# AT90PWM1 register map
Vendor: Atmel; File version: 1.0
CPU: other r0p0, little endian, no MPU, no FPU, 4 interrupt priority bits
Registers are 8-bit, read-write, reset 0x0 unless marked. A register's access mark holds for its fields unless they carry their own. Offsets are from the block's base; [hi:lo] are bit positions; {n}, {i} and the like mark numbered series.

## BOOT_LOAD — Bootloader
Base 0x00800057
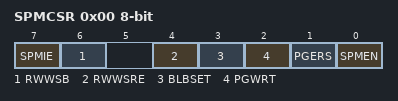
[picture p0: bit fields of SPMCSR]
0x00 SPMCSR — Store Program Memory Control Register
  [7] SPMIE — SPM Interrupt Enable
  [6] RWWSB — Read While Write Section Busy
  [4] RWWSRE — Read While Write section read enable
  [3] BLBSET — Boot Lock Bit Set
  [2] PGWRT — Page Write
  [1] PGERS — Page Erase
  [0] SPMEN — Store Program Memory Enable

## CPU — CPU Registers
Base 0x00800039
0x00 GPIOR1 — General Purpose IO Register 1
  [7:0] GPIOR — General Purpose IO Register 1 bis
0x01 GPIOR2 — General Purpose IO Register 2
  [7:0] GPIOR — General Purpose IO Register 2 bis
0x02 GPIOR3 — General Purpose IO Register 3
  [7:0] GPIOR — General Purpose IO Register 3 bis
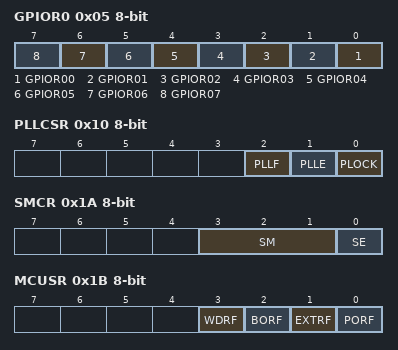
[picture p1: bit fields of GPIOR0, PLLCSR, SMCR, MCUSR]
0x05 GPIOR0 — General Purpose IO Register 0
  [n] GPIOR{n:02} (n=0..7) — General Purpose IO Register 0 bit {n}
0x10 PLLCSR — PLL Control And Status Register
  [2] PLLF — PLL Factor
  [1] PLLE — PLL Enable
  [0] PLOCK — PLL Lock Detector
0x1A SMCR — Sleep Mode Control Register
  [3:1] SM — Sleep Mode Select bits
    0=IDLE; 1=ADC (ADC Noise Reduction (If Available)); 2=PDOWN (Power Down); 6=STDBY (Standby)
  [0] SE — Sleep Enable
0x1B MCUSR — MCU Status Register
  [3] WDRF — Watchdog Reset Flag
  [2] BORF — Brown-out Reset Flag
  [1] EXTRF — External Reset Flag
  [0] PORF — Power-on reset flag
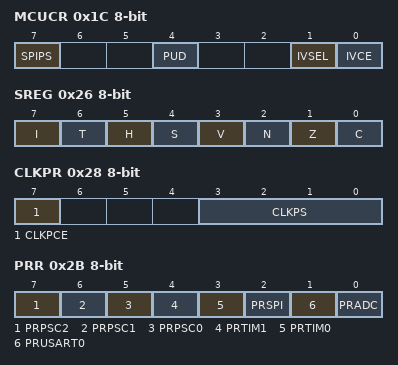
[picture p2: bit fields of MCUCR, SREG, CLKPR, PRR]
0x1C MCUCR — MCU Control Register
  [7] SPIPS — SPI Pin Select
  [4] PUD — Pull-up disable
  [1] IVSEL — Interrupt Vector Select
  [0] IVCE — Interrupt Vector Change Enable
0x24 SP 16-bit (reset mask 0xFF) — Stack Pointer
0x26 SREG — Status Register
  [7] I — Global Interrupt Enable
  [6] T — Bit Copy Storage
  [5] H — Half Carry Flag
  [4] S — Sign Bit
  [3] V — Two's Complement Overflow Flag
  [2] N — Negative Flag
  [1] Z — Zero Flag
  [0] C — Carry Flag
0x28 CLKPR
  [7] CLKPCE
  [3:0] CLKPS
    0=1; 1=2; 2=4; 3=8; 4=16; 5=32; 6=64; 7=128; 8=256
0x2B PRR — Power Reduction Register
  [7] PRPSC2 — Power Reduction PSC2
  [6] PRPSC1 — Power Reduction PSC1
  [5] PRPSC0 — Power Reduction PSC0
  [4] PRTIM1 — Power Reduction Timer/Counter1
  [3] PRTIM0 — Power Reduction Timer/Counter0
  [2] PRSPI — Power Reduction Serial Peripheral Interface
  [1] PRUSART0 — Power Reduction USART
  [0] PRADC — Power Reduction ADC
0x2D OSCCAL — Oscillator Calibration Value (read-only for debugger)
  [7:0] OSCCAL — Oscillator Calibration

## EEPROM
Base 0x0080003F
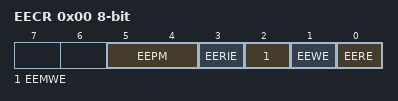
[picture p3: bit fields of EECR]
0x00 EECR — EEPROM Control Register
  [5:4] EEPM — EEPROM Programming Mode
  [3] EERIE — EEPROM Ready Interrupt Enable
  [2] EEMWE — EEPROM Master Write Enable
  [1] EEWE — EEPROM Write Enable
  [0] EERE — EEPROM Read Enable
0x01 EEDR — EEPROM Data Register
  [7:0] EEDR — EEPROM Data Bits
0x02 EEAR 16-bit (reset mask 0xFF) — EEPROM Read/Write Access Bytes
  [11:0] EEAR — EEPROM Address bytes

## EXINT — External Interrupts
Base 0x0080003C
0x00 EIFR — External Interrupt Flag Register (read-only for debugger)
  [3:0] INTF — External Interrupt Flags
0x01 EIMSK — External Interrupt Mask Register
  [3:0] INT — External Interrupt Mask
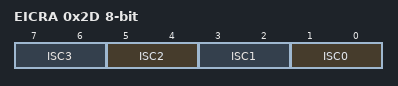
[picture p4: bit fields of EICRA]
0x2D EICRA — External Interrupt Control Register A
  [all] fields
    0=LOW_LEVEL_OF_INTX; 1=ANY_LOGICAL_CHANGE_OF_INTX; 2=FALLING_EDGE_OF_INTX; 3=RISING_EDGE_OF_INTX
  [2n+1:2n] ISC{n} (n=0..3) — External Interrupt Sense Control Bit

## PORTB — I/O Port
Base 0x00800023
0x00 PINB — Port B Input Pins (read-only for debugger)
0x01 DDRB — Port B Data Direction Register
0x02 PORTB — Port B Data Register

## PORTD — I/O Port
Base 0x00800029
0x00 PIND — Port D Input Pins (read-only for debugger)
0x01 DDRD — Port D Data Direction Register
0x02 PORTD — Port D Data Register
